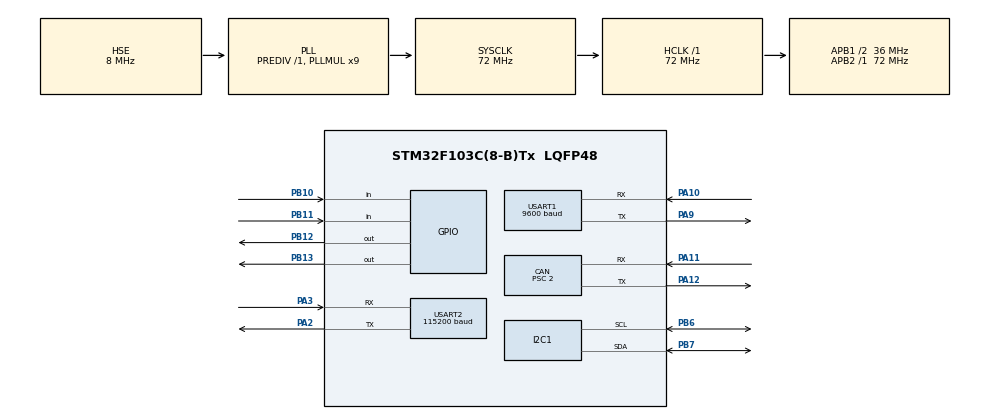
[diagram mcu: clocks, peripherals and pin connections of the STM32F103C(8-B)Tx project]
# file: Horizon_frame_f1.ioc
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CAN.BS1=CAN_BS1_13TQ
CAN.BS2=CAN_BS2_4TQ
CAN.CalculateBaudRate=1000000
CAN.CalculateTimeBit=1000
CAN.CalculateTimeQuantum=55.55555555555556
CAN.NART=ENABLE
CAN.Prescaler=2
Dma.Request0=USART2_TX
Dma.Request1=USART2_RX
Dma.Request2=USART1_RX
Dma.Request3=USART1_TX
Dma.USART1_RX.2.Direction=DMA_PERIPH_TO_MEMORY
Dma.USART1_RX.2.Instance=DMA1_Channel5
Dma.USART1_RX.2.MemDataAlignment=DMA_MDATAALIGN_BYTE
Dma.USART1_RX.2.MemInc=DMA_MINC_ENABLE
Dma.USART1_RX.2.Mode=DMA_NORMAL
Dma.USART1_RX.2.PeriphDataAlignment=DMA_PDATAALIGN_BYTE
Dma.USART1_RX.2.PeriphInc=DMA_PINC_DISABLE
Dma.USART1_RX.2.Priority=DMA_PRIORITY_VERY_HIGH
Dma.USART1_TX.3.Direction=DMA_MEMORY_TO_PERIPH
Dma.USART1_TX.3.Instance=DMA1_Channel4
Dma.USART1_TX.3.MemDataAlignment=DMA_MDATAALIGN_BYTE
Dma.USART1_TX.3.MemInc=DMA_MINC_ENABLE
Dma.USART1_TX.3.Mode=DMA_NORMAL
Dma.USART1_TX.3.PeriphDataAlignment=DMA_PDATAALIGN_BYTE
Dma.USART1_TX.3.PeriphInc=DMA_PINC_DISABLE
Dma.USART1_TX.3.Priority=DMA_PRIORITY_VERY_HIGH
Dma.USART2_RX.1.Direction=DMA_PERIPH_TO_MEMORY
Dma.USART2_RX.1.Instance=DMA1_Channel6
Dma.USART2_RX.1.MemDataAlignment=DMA_MDATAALIGN_BYTE
Dma.USART2_RX.1.MemInc=DMA_MINC_ENABLE
Dma.USART2_RX.1.Mode=DMA_NORMAL
Dma.USART2_RX.1.PeriphDataAlignment=DMA_PDATAALIGN_BYTE
Dma.USART2_RX.1.PeriphInc=DMA_PINC_DISABLE
Dma.USART2_RX.1.Priority=DMA_PRIORITY_MEDIUM
Dma.USART2_TX.0.Direction=DMA_MEMORY_TO_PERIPH
Dma.USART2_TX.0.Instance=DMA1_Channel7
Dma.USART2_TX.0.MemDataAlignment=DMA_MDATAALIGN_BYTE
Dma.USART2_TX.0.MemInc=DMA_MINC_ENABLE
Dma.USART2_TX.0.Mode=DMA_NORMAL
Dma.USART2_TX.0.PeriphDataAlignment=DMA_PDATAALIGN_BYTE
Dma.USART2_TX.0.PeriphInc=DMA_PINC_DISABLE
Dma.USART2_TX.0.Priority=DMA_PRIORITY_MEDIUM
FREERTOS.INCLUDE_eTaskGetState=0
FREERTOS.INCLUDE_pcTaskGetTaskName=0
FREERTOS.INCLUDE_uxTaskGetStackHighWaterMark=0
FREERTOS.INCLUDE_uxTaskPriorityGet=0
FREERTOS.INCLUDE_vTaskCleanUpResources=0
FREERTOS.INCLUDE_vTaskDelay=1
FREERTOS.INCLUDE_vTaskDelayUntil=1
FREERTOS.INCLUDE_vTaskDelete=0
FREERTOS.INCLUDE_vTaskPrioritySet=0
FREERTOS.INCLUDE_vTaskSuspend=1
FREERTOS.INCLUDE_xEventGroupSetBitFromISR=0
FREERTOS.INCLUDE_xQueueGetMutexHolder=0
FREERTOS.INCLUDE_xSemaphoreGetMutexHolder=0
FREERTOS.INCLUDE_xTaskAbortDelay=0
FREERTOS.INCLUDE_xTaskGetCurrentTaskHandle=0
FREERTOS.INCLUDE_xTaskGetHandle=0
FREERTOS.INCLUDE_xTaskResumeFromISR=1
FREERTOS.INCLUDE_xTimerPendFunctionCall=0
FREERTOS.Mutexes01=motorOffline,Dynamic,NULL,Available
FREERTOS.Tasks01=defaultTask,0,256,StartDefaultTask,As weak,NULL,Dynamic,NULL,NULL;gimbalTask,2,256,StartGimbalTask,As weak,NULL,Dynamic,NULL,NULL;monitorTask,0,128,StartMonitorTask,As weak,NULL,Dynamic,NULL,NULL
FREERTOS.configGENERATE_RUN_TIME_STATS=0
FREERTOS.configUSE_COUNTING_SEMAPHORES=1
FREERTOS.configUSE_RECURSIVE_MUTEXES=1
FREERTOS.configUSE_STATS_FORMATTING_FUNCTIONS=0
FREERTOS.configUSE_TIMERS=1
FREERTOS.configUSE_TRACE_FACILITY=0
I2C1.I2C_Mode=I2C_Standard
Mcu.Family=STM32F1
Mcu.Name=STM32F103C(8-B)Tx
Mcu.Package=LQFP48
NVIC.DMA1_Channel4_IRQn=true\:5\:0\:false\:false\:true\:true\:false\:true\:true
NVIC.DMA1_Channel5_IRQn=true\:5\:0\:false\:false\:true\:true\:false\:true\:true
NVIC.DMA1_Channel6_IRQn=true\:5\:0\:false\:false\:true\:true\:false\:true\:true
NVIC.DMA1_Channel7_IRQn=true\:5\:0\:false\:false\:true\:true\:false\:true\:true
NVIC.PriorityGroup=NVIC_PRIORITYGROUP_4
NVIC.TIM1_UP_IRQn=true\:15\:0\:false\:false\:true\:false\:false\:true\:true
NVIC.TIM2_IRQn=true\:6\:0\:true\:false\:true\:true\:true\:true\:true
NVIC.TimeBase=TIM1_UP_IRQn
NVIC.TimeBaseIP=TIM1
NVIC.USART1_IRQn=true\:5\:0\:true\:false\:true\:true\:true\:true\:true
NVIC.USART2_IRQn=true\:6\:0\:true\:false\:true\:true\:true\:true\:true
NVIC.USB_HP_CAN1_TX_IRQn=true\:5\:0\:false\:false\:true\:true\:true\:true\:true
NVIC.USB_LP_CAN1_RX0_IRQn=true\:5\:0\:false\:false\:true\:true\:true\:true\:true
PA10.Mode=Asynchronous
PA10.Signal=USART1_RX
PA11.GPIO_PuPd=GPIO_PULLUP
PA11.Mode=CAN_Activate
PA11.Signal=CAN_RX
PA12.Mode=CAN_Activate
PA12.Signal=CAN_TX
PA13.Mode=Serial_Wire
PA13.Signal=SYS_JTMS-SWDIO
PA14.Mode=Serial_Wire
PA14.Signal=SYS_JTCK-SWCLK
PA2.Mode=Asynchronous
PA2.Signal=USART2_TX
PA3.Mode=Asynchronous
PA3.Signal=USART2_RX
PA9.Mode=Asynchronous
PA9.Signal=USART1_TX
PB10.GPIO_PuPd=GPIO_PULLUP
PB10.Signal=GPIO_Input
PB11.GPIO_PuPd=GPIO_PULLUP
PB11.Signal=GPIO_Input
PB12.GPIO_PuPd=GPIO_PULLUP
PB12.GPIO_Speed=GPIO_SPEED_FREQ_HIGH
PB12.Signal=GPIO_Output
PB13.GPIO_PuPd=GPIO_PULLUP
PB13.GPIO_Speed=GPIO_SPEED_FREQ_HIGH
PB13.Signal=GPIO_Output
PB6.Mode=I2C
PB6.Signal=I2C1_SCL
PB7.Mode=I2C
PB7.Signal=I2C1_SDA
PC14-OSC32_IN.Mode=LSE-External-Oscillator
PC14-OSC32_IN.Signal=RCC_OSC32_IN
PC15-OSC32_OUT.Mode=LSE-External-Oscillator
PC15-OSC32_OUT.Signal=RCC_OSC32_OUT
PD0-OSC_IN.Mode=HSE-External-Oscillator
PD0-OSC_IN.Signal=RCC_OSC_IN
PD1-OSC_OUT.Mode=HSE-External-Oscillator
PD1-OSC_OUT.Signal=RCC_OSC_OUT
ProjectManager.HeapSize=0x200
ProjectManager.StackSize=0x400
ProjectManager.TargetToolchain=MDK-ARM V5.32
RCC.AHBFreq_Value=72000000
RCC.APB1CLKDivider=RCC_HCLK_DIV2
RCC.APB1Freq_Value=36000000
RCC.APB1TimFreq_Value=72000000
RCC.APB2Freq_Value=72000000
RCC.APB2TimFreq_Value=72000000
RCC.HCLKFreq_Value=72000000
RCC.PLLMUL=RCC_PLL_MUL9
RCC.PLLSourceVirtual=RCC_PLLSOURCE_HSE
RCC.SYSCLKFreq_VALUE=72000000
RCC.SYSCLKSource=RCC_SYSCLKSOURCE_PLLCLK
RCC.USBFreq_Value=72000000
TIM2.AutoReloadPreload=TIM_AUTORELOAD_PRELOAD_ENABLE
TIM2.Period=5000-1
TIM2.Prescaler=7200-1
USART1.BaudRate=9600
USART1.VirtualMode=VM_ASYNC
USART2.BaudRate=115200
USART2.VirtualMode=VM_ASYNC
VP_FREERTOS_VS_CMSIS_V1.Mode=CMSIS_V1
VP_SYS_VS_tim1.Mode=TIM1
VP_TIM2_VS_ClockSourceINT.Mode=Internal
board=custom

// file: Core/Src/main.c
/* USER CODE BEGIN Header */
/**
  ******************************************************************************
  * @file           : main.c
  * @brief          : Main program body
  ******************************************************************************
  * @attention
  *
  * Copyright (c) 2025 STMicroelectronics.
  * All rights reserved.
  *
  * This software is licensed under terms that can be found in the LICENSE file
  * in the root directory of this software component.
  * If no LICENSE file comes with this software, it is provided AS-IS.
  *
  ******************************************************************************
  */
/* USER CODE END Header */
#include "main.h"
#include "cmsis_os.h"
#include "can.h"
#include "dma.h"
#include "i2c.h"
#include "tim.h"
#include "usart.h"
#include "gpio.h"

/* USER CODE BEGIN Includes */
#include "gps.h"
/* USER CODE END Includes */

void SystemClock_Config(void);
void MX_FREERTOS_Init(void);

int main(void)
{

  /* MCU Configuration--------------------------------------------------------*/

  /* Reset of all peripherals, Initializes the Flash interface and the Systick. */
  HAL_Init();

  /* Configure the system clock */
  SystemClock_Config();

  /* Initialize all configured peripherals */
  MX_GPIO_Init();
  MX_DMA_Init();
  MX_CAN_Init();
  MX_TIM2_Init();
  MX_USART2_UART_Init();
  MX_USART1_UART_Init();
  MX_I2C1_Init();

  /* Call init function for freertos objects (in cmsis_os2.c) */
  MX_FREERTOS_Init();

  /* Start scheduler */
  osKernelStart();

  /* We should never get here as control is now taken by the scheduler */

  /* Infinite loop */
  while (1)
  {

  }
}

void SystemClock_Config(void)
{
  RCC_OscInitTypeDef RCC_OscInitStruct = {0};
  RCC_ClkInitTypeDef RCC_ClkInitStruct = {0};

  /** Initializes the RCC Oscillators according to the specified parameters
  * in the RCC_OscInitTypeDef structure.
  */
  RCC_OscInitStruct.OscillatorType = RCC_OSCILLATORTYPE_HSE;
  RCC_OscInitStruct.HSEState = RCC_HSE_ON;
  RCC_OscInitStruct.HSEPredivValue = RCC_HSE_PREDIV_DIV1;
  RCC_OscInitStruct.HSIState = RCC_HSI_ON;
  RCC_OscInitStruct.PLL.PLLState = RCC_PLL_ON;
  RCC_OscInitStruct.PLL.PLLSource = RCC_PLLSOURCE_HSE;
  RCC_OscInitStruct.PLL.PLLMUL = RCC_PLL_MUL9;
  if (HAL_RCC_OscConfig(&RCC_OscInitStruct) != HAL_OK)
  {
    Error_Handler();
  }

  /** Initializes the CPU, AHB and APB buses clocks
  */
  RCC_ClkInitStruct.ClockType = RCC_CLOCKTYPE_HCLK|RCC_CLOCKTYPE_SYSCLK
                              |RCC_CLOCKTYPE_PCLK1|RCC_CLOCKTYPE_PCLK2;
  RCC_ClkInitStruct.SYSCLKSource = RCC_SYSCLKSOURCE_PLLCLK;
  RCC_ClkInitStruct.AHBCLKDivider = RCC_SYSCLK_DIV1;
  RCC_ClkInitStruct.APB1CLKDivider = RCC_HCLK_DIV2;
  RCC_ClkInitStruct.APB2CLKDivider = RCC_HCLK_DIV1;

  if (HAL_RCC_ClockConfig(&RCC_ClkInitStruct, FLASH_LATENCY_2) != HAL_OK)
  {
    Error_Handler();
  }
}

void HAL_TIM_PeriodElapsedCallback(TIM_HandleTypeDef *htim)
{
  if (htim->Instance == TIM1)
  {
    HAL_IncTick();
  }
}

void Error_Handler(void)
{
  __disable_irq();
  while (1)
  {
  }
}

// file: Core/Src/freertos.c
/* USER CODE BEGIN Header */
/**
  ******************************************************************************
  * File Name          : freertos.c
  * Description        : Code for freertos applications
  ******************************************************************************
  * @attention
  *
  * Copyright (c) 2025 STMicroelectronics.
  * All rights reserved.
  *
  * This software is licensed under terms that can be found in the LICENSE file
  * in the root directory of this software component.
  * If no LICENSE file comes with this software, it is provided AS-IS.
  *
  ******************************************************************************
  */
/* USER CODE END Header */

#include "FreeRTOS.h"
#include "task.h"
#include "main.h"
#include "cmsis_os.h"

osThreadId defaultTaskHandle;
osThreadId gimbalTaskHandle;
osThreadId monitorTaskHandle;
osMutexId motorOfflineHandle;

void StartDefaultTask(void const * argument);
void StartGimbalTask(void const * argument);
void StartMonitorTask(void const * argument);

void MX_FREERTOS_Init(void); /* (MISRA C 2004 rule 8.1) */

/* GetIdleTaskMemory prototype (linked to static allocation support) */
void vApplicationGetIdleTaskMemory( StaticTask_t **ppxIdleTaskTCBBuffer, StackType_t **ppxIdleTaskStackBuffer, uint32_t *pulIdleTaskStackSize );

/* GetTimerTaskMemory prototype (linked to static allocation support) */
void vApplicationGetTimerTaskMemory( StaticTask_t **ppxTimerTaskTCBBuffer, StackType_t **ppxTimerTaskStackBuffer, uint32_t *pulTimerTaskStackSize );

/* USER CODE BEGIN GET_IDLE_TASK_MEMORY */
static StaticTask_t xIdleTaskTCBBuffer;
static StackType_t xIdleStack[configMINIMAL_STACK_SIZE];

void vApplicationGetIdleTaskMemory( StaticTask_t **ppxIdleTaskTCBBuffer, StackType_t **ppxIdleTaskStackBuffer, uint32_t *pulIdleTaskStackSize )
{
  *ppxIdleTaskTCBBuffer = &xIdleTaskTCBBuffer;
  *ppxIdleTaskStackBuffer = &xIdleStack[0];
  *pulIdleTaskStackSize = configMINIMAL_STACK_SIZE;
  /* place for user code */
}
/* USER CODE END GET_IDLE_TASK_MEMORY */

/* USER CODE BEGIN GET_TIMER_TASK_MEMORY */
static StaticTask_t xTimerTaskTCBBuffer;
static StackType_t xTimerStack[configTIMER_TASK_STACK_DEPTH];

void vApplicationGetTimerTaskMemory( StaticTask_t **ppxTimerTaskTCBBuffer, StackType_t **ppxTimerTaskStackBuffer, uint32_t *pulTimerTaskStackSize )
{
  *ppxTimerTaskTCBBuffer = &xTimerTaskTCBBuffer;
  *ppxTimerTaskStackBuffer = &xTimerStack[0];
  *pulTimerTaskStackSize = configTIMER_TASK_STACK_DEPTH;
  /* place for user code */
}
/* USER CODE END GET_TIMER_TASK_MEMORY */

void MX_FREERTOS_Init(void) {
  /* Create the mutex(es) */
  /* definition and creation of motorOffline */
  osMutexDef(motorOffline);
  motorOfflineHandle = osMutexCreate(osMutex(motorOffline));

  /* Create the thread(s) */
  /* definition and creation of defaultTask */
  osThreadDef(defaultTask, StartDefaultTask, osPriorityNormal, 0, 256);
  defaultTaskHandle = osThreadCreate(osThread(defaultTask), NULL);

  /* definition and creation of gimbalTask */
  osThreadDef(gimbalTask, StartGimbalTask, osPriorityHigh, 0, 256);
  gimbalTaskHandle = osThreadCreate(osThread(gimbalTask), NULL);

  /* definition and creation of monitorTask */
  osThreadDef(monitorTask, StartMonitorTask, osPriorityNormal, 0, 128);
  monitorTaskHandle = osThreadCreate(osThread(monitorTask), NULL);

}

__weak void StartDefaultTask(void const * argument)
{
  for(;;)
  {
    osDelay(1);
  }
}

__weak void StartGimbalTask(void const * argument)
{
  for(;;)
  {
    osDelay(1);
  }
}

__weak void StartMonitorTask(void const * argument)
{
  for(;;)
  {
    osDelay(1);
  }
}
